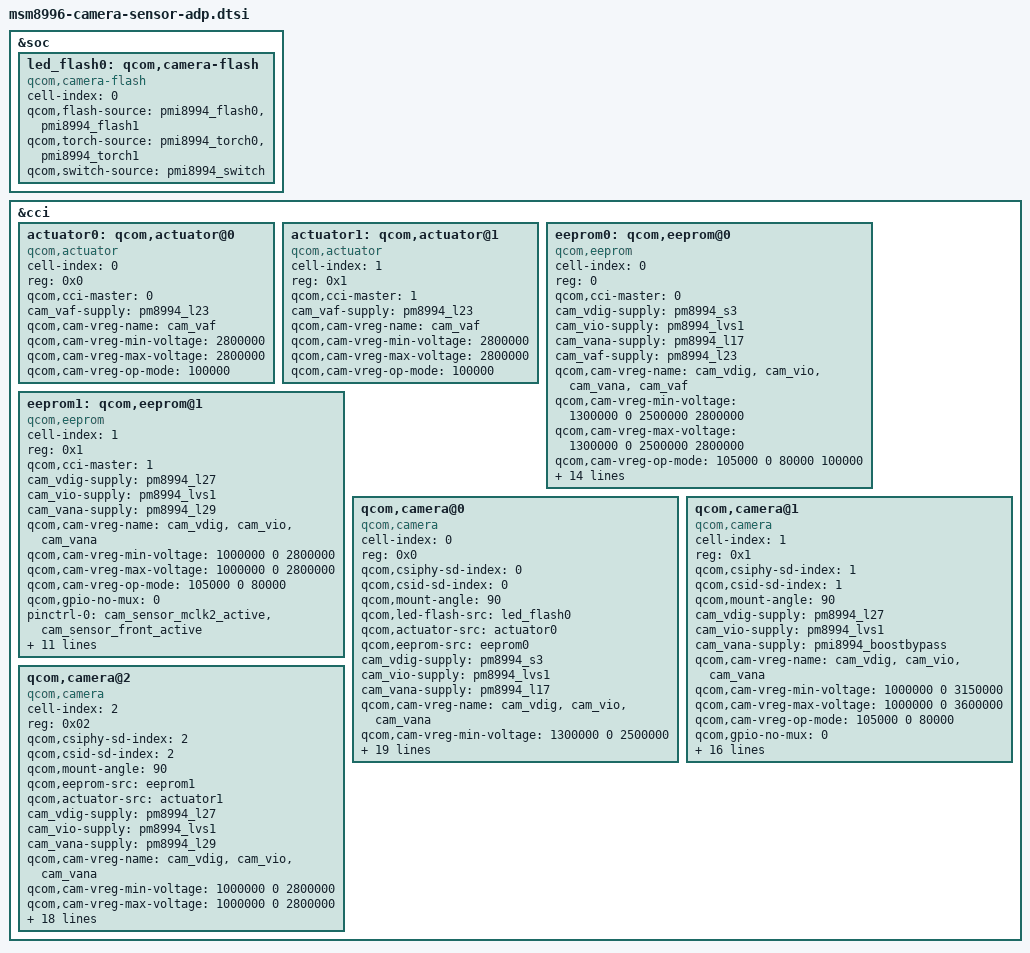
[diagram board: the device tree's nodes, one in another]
/*
 * Copyright (c) 2015 The Linux Foundation. All rights reserved.
 *
 * This program is free software; you can redistribute it and/or modify
 * it under the terms of the GNU General Public License version 2 and
 * only version 2 as published by the Free Software Foundation.
 *
 * This program is distributed in the hope that it will be useful,
 * but WITHOUT ANY WARRANTY; without even the implied warranty of
 * MERCHANTABILITY or FITNESS FOR A PARTICULAR PURPOSE.  See the
 * GNU General Public License for more details.
 */

&soc {
	led_flash0: qcom,camera-flash {
		cell-index = <0>;
		compatible = "qcom,camera-flash";
		qcom,flash-source = <&pmi8994_flash0 &pmi8994_flash1>;
		qcom,torch-source = <&pmi8994_torch0 &pmi8994_torch1>;
		qcom,switch-source = <&pmi8994_switch>;
	};
};

&cci {
	actuator0: qcom,actuator@0 {
		cell-index = <0>;
		reg = <0x0>;
		compatible = "qcom,actuator";
		qcom,cci-master = <0>;
		cam_vaf-supply = <&pm8994_l23>;
		qcom,cam-vreg-name = "cam_vaf";
		qcom,cam-vreg-min-voltage = <2800000>;
		qcom,cam-vreg-max-voltage = <2800000>;
		qcom,cam-vreg-op-mode = <100000>;
	};

	actuator1: qcom,actuator@1 {
		cell-index = <1>;
		reg = <0x1>;
		compatible = "qcom,actuator";
		qcom,cci-master = <1>;
		cam_vaf-supply = <&pm8994_l23>;
		qcom,cam-vreg-name = "cam_vaf";
		qcom,cam-vreg-min-voltage = <2800000>;
		qcom,cam-vreg-max-voltage = <2800000>;
		qcom,cam-vreg-op-mode = <100000>;
	};

	eeprom0: qcom,eeprom@0 {
		cell-index = <0>;
		reg = <0>;
		compatible = "qcom,eeprom";
		qcom,cci-master = <0>;
		cam_vdig-supply = <&pm8994_s3>;
		cam_vio-supply = <&pm8994_lvs1>;
		cam_vana-supply = <&pm8994_l17>;
		cam_vaf-supply = <&pm8994_l23>;
		qcom,cam-vreg-name = "cam_vdig", "cam_vio", "cam_vana",
			"cam_vaf";
		qcom,cam-vreg-min-voltage = <1300000 0 2500000 2800000>;
		qcom,cam-vreg-max-voltage = <1300000 0 2500000 2800000>;
		qcom,cam-vreg-op-mode = <105000 0 80000 100000>;
		qcom,gpio-no-mux = <0>;
		pinctrl-names = "cam_default", "cam_suspend";
		pinctrl-0 = <&cam_sensor_mclk0_active &cam_sensor_rear_active>;
		pinctrl-1 = <&cam_sensor_mclk0_suspend
			&cam_sensor_rear_suspend>;
		gpios = <&tlmm 13 0>,
			<&tlmm 30 0>,
			<&tlmm 29 0>;
		qcom,gpio-reset = <1>;
		qcom,gpio-standby = <2>;
		qcom,gpio-req-tbl-num = <0 1 2>;
		qcom,gpio-req-tbl-flags = <1 0 0>;
		qcom,gpio-req-tbl-label = "CAMIF_MCLK0",
					  "CAM_RESET0",
					  "CAM_STANDBY0";
		clocks = <&clock_mmss clk_mclk0_clk_src>,
				<&clock_mmss clk_camss_mclk0_clk>;
		clock-names = "cam_src_clk", "cam_clk";
	};

	eeprom1: qcom,eeprom@1 {
		cell-index = <1>;
		reg = <0x1>;
		compatible = "qcom,eeprom";
		qcom,cci-master = <1>;
		cam_vdig-supply = <&pm8994_l27>;
		cam_vio-supply = <&pm8994_lvs1>;
		cam_vana-supply = <&pm8994_l29>;
		qcom,cam-vreg-name = "cam_vdig", "cam_vio", "cam_vana";
		qcom,cam-vreg-min-voltage = <1000000 0 2800000>;
		qcom,cam-vreg-max-voltage = <1000000 0 2800000>;
		qcom,cam-vreg-op-mode = <105000 0 80000>;
		qcom,gpio-no-mux = <0>;
		pinctrl-names = "cam_default", "cam_suspend";
		pinctrl-0 = <&cam_sensor_mclk2_active &cam_sensor_front_active>;
		pinctrl-1 = <&cam_sensor_mclk2_suspend
			&cam_sensor_front_suspend>;
		gpios = <&tlmm 15 0>,
			<&tlmm 23 0>,
			<&tlmm 26 0>;
		qcom,gpio-reset = <1>;
		qcom,gpio-standby = <2>;
		qcom,gpio-req-tbl-num = <0 1 2>;
		qcom,gpio-req-tbl-flags = <1 0 0>;
		qcom,gpio-req-tbl-label = "CAMIF_MCLK2",
					  "CAM_RESET2",
					  "CAM_STANDBY2";
		clocks = <&clock_mmss clk_mclk2_clk_src>,
			<&clock_mmss clk_camss_mclk2_clk>;
		clock-names = "cam_src_clk", "cam_clk";
	};

	qcom,camera@0 {
		cell-index = <0>;
		compatible = "qcom,camera";
		reg = <0x0>;
		qcom,csiphy-sd-index = <0>;
		qcom,csid-sd-index = <0>;
		qcom,mount-angle = <90>;
		qcom,led-flash-src = <&led_flash0>;
		qcom,actuator-src = <&actuator0>;
		qcom,eeprom-src = <&eeprom0>;
		cam_vdig-supply = <&pm8994_s3>;
		cam_vio-supply = <&pm8994_lvs1>;
		cam_vana-supply = <&pm8994_l17>;
		qcom,cam-vreg-name = "cam_vdig", "cam_vio", "cam_vana";
		qcom,cam-vreg-min-voltage = <1300000 0 2500000>;
		qcom,cam-vreg-max-voltage = <1300000 0 2500000>;
		qcom,cam-vreg-op-mode = <105000 0 80000>;
		qcom,gpio-no-mux = <0>;
		pinctrl-names = "cam_default", "cam_suspend";
		pinctrl-0 = <&cam_sensor_mclk0_active &cam_sensor_rear_active>;
		pinctrl-1 = <&cam_sensor_mclk0_suspend
				&cam_sensor_rear_suspend>;
		gpios = <&tlmm 13 0>,
			<&tlmm 30 0>,
			<&tlmm 29 0>;
		qcom,gpio-reset = <1>;
		qcom,gpio-standby = <2>;
		qcom,gpio-req-tbl-num = <0 1 2>;
		qcom,gpio-req-tbl-flags = <1 0 0>;
		qcom,gpio-req-tbl-label = "CAMIF_MCLK0",
					  "CAM_RESET0",
					  "CAM_STANDBY0";
		qcom,sensor-position = <0>;
		qcom,sensor-mode = <0>;
		qcom,cci-master = <0>;
		status = "ok";
		clocks = <&clock_mmss clk_mclk0_clk_src>,
				<&clock_mmss clk_camss_mclk0_clk>;
		clock-names = "cam_src_clk", "cam_clk";
	};

	qcom,camera@1 {
		cell-index = <1>;
		compatible = "qcom,camera";
		reg = <0x1>;
		qcom,csiphy-sd-index = <1>;
		qcom,csid-sd-index = <1>;
		qcom,mount-angle = <90>;
		cam_vdig-supply = <&pm8994_l27>;
		cam_vio-supply = <&pm8994_lvs1>;
		cam_vana-supply = <&pmi8994_boostbypass>;
		qcom,cam-vreg-name = "cam_vdig", "cam_vio", "cam_vana";
		qcom,cam-vreg-min-voltage = <1000000 0 3150000>;
		qcom,cam-vreg-max-voltage = <1000000 0 3600000>;
		qcom,cam-vreg-op-mode = <105000 0 80000>;
		qcom,gpio-no-mux = <0>;
		pinctrl-names = "cam_default", "cam_suspend";
		pinctrl-0 = <&cam_sensor_mclk1_active &cam_sensor_rear2_active>;
		pinctrl-1 = <&cam_sensor_mclk1_suspend
				&cam_sensor_rear2_suspend>;
		gpios = <&tlmm 14 0>,
			<&tlmm 63 0>,
			<&tlmm 62 0>;
		qcom,gpio-reset = <1>;
		qcom,gpio-standby = <2>;
		qcom,gpio-req-tbl-num = <0 1 2>;
		qcom,gpio-req-tbl-flags = <1 0 0>;
		qcom,gpio-req-tbl-label = "CAMIF_MCLK1",
					  "CAM_RESET1",
					  "CAM_STANDBY1";
		qcom,sensor-position = <0>;
		qcom,sensor-mode = <0>;
		qcom,cci-master = <0>;
		status = "ok";
		clocks = <&clock_mmss clk_mclk1_clk_src>,
			<&clock_mmss clk_camss_mclk1_clk>;
		clock-names = "cam_src_clk", "cam_clk";
	};

	qcom,camera@2 {
		cell-index = <2>;
		compatible = "qcom,camera";
		reg = <0x02>;
		qcom,csiphy-sd-index = <2>;
		qcom,csid-sd-index = <2>;
		qcom,mount-angle = <90>;
		qcom,eeprom-src = <&eeprom1>;
		qcom,actuator-src = <&actuator1>;
		cam_vdig-supply = <&pm8994_l27>;
		cam_vio-supply = <&pm8994_lvs1>;
		cam_vana-supply = <&pm8994_l29>;
		qcom,cam-vreg-name = "cam_vdig", "cam_vio", "cam_vana";
		qcom,cam-vreg-min-voltage = <1000000 0 2800000>;
		qcom,cam-vreg-max-voltage = <1000000 0 2800000>;
		qcom,cam-vreg-op-mode = <105000 0 80000>;
		qcom,gpio-no-mux = <0>;
		pinctrl-names = "cam_default", "cam_suspend";
		pinctrl-0 = <&cam_sensor_mclk2_active &cam_sensor_front_active>;
		pinctrl-1 = <&cam_sensor_mclk2_suspend
				&cam_sensor_front_suspend>;
		gpios = <&tlmm 15 0>,
			<&tlmm 23 0>,
			<&tlmm 26 0>;
		qcom,gpio-reset = <1>;
		qcom,gpio-standby = <2>;
		qcom,gpio-req-tbl-num = <0 1 2>;
		qcom,gpio-req-tbl-flags = <1 0 0>;
		qcom,gpio-req-tbl-label = "CAMIF_MCLK2",
					  "CAM_RESET2",
					  "CAM_STANDBY2";
		qcom,sensor-position = <1>;
		qcom,sensor-mode = <0>;
		qcom,cci-master = <1>;
		status = "ok";
		clocks = <&clock_mmss clk_mclk2_clk_src>,
			<&clock_mmss clk_camss_mclk2_clk>;
		clock-names = "cam_src_clk", "cam_clk";
	};
};
